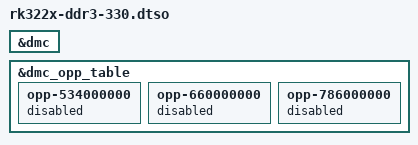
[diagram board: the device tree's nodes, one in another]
/dts-v1/;
/plugin/;

&dmc {
	status = "okay";
};

&dmc_opp_table {
	opp-534000000 {
		status = "disabled";
	};
	opp-660000000 {
		status = "disabled";
	};
	opp-786000000 {
		status = "disabled";
	};
};
